# CY8C5888LTQ_LP097 register map
File version: 0.1
CY8C58LP
Registers are 8-bit, read-write, no defined reset value unless marked. A register's access mark holds for its fields unless they carry their own. Offsets are from the block's base; lines under a group give offsets from that group; [hi:lo] are bit positions; {n}, {i} and the like mark numbered series; 'fields as' and 'values as' point back to an identical list; <NAME> marks a mode.

## Memory map
0x00000000 ADC_SAR_1 — SAR ADC
0x00000000 I2C
0x00000000 EB_Status_Reg_2
0x00000000 EB_Status_Reg_1
0x00000000 USBUART — USBFS
0x00000000 ADC_SAR_2 — SAR ADC
0x00000000 ENGINE_DECODER
0x00000000 ENGINE_DECODER_Cnt16
0x00000000 ENGINE_Direction
0x00000000 UART_LOG — UART
0x00000000 ENGINE_PWM
0x00000000 UART_PSOC — UART

## ADC_SAR_1 — SAR ADC
Base 0x00000000
0x40004614 SAR_TR0 — SAR trim register
{0x40005900+i} SAR_CSR{i} (i=0..6) — SAR status and control register {i}
0x40005B20 SAR_SW0 — SAR Analog Routing Register 0
{0x40005B20+i} SAR_SW{i} (i=2..4) — SAR Analog Routing Register {i}
0x40005B26 SAR_SW6 — SAR Analog Routing Register 6
0x40005B27 SAR_CLK — SAR Clock Selection Register
0x40005BA0 SAR_WRK 16-bit — SAR working register

## EB_Status_Reg_2
Base 0x00000000
0x40006566 EB_Status_Reg_2_STATUS_REG
0x40006586 EB_Status_Reg_2_MASK_REG
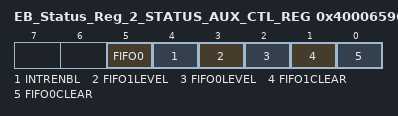
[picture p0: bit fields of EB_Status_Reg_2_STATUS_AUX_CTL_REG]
0x40006596 EB_Status_Reg_2_STATUS_AUX_CTL_REG
  [5] FIFO0 — FIFO0 clear
    1=ENABLED (Enable counter); 0=DISABLED (Disable counter)
  [4] INTRENBL — Enables or disables the Interrupt
    1=ENABLED (Interrupt enabled); 0=DISABLED (Interrupt disabled)
  [3] FIFO1LEVEL — FIFO level
    1=ENABLED (FIFO LVL: input mode: FIFO at least 1/2 empty; output mode: FIFO at least 1/2 full); 0=DISABLED (FIFO LVL: input mode: FIFO not full; output mode: FIFO not empty)
  [2] FIFO0LEVEL — FIFO level
    values as FIFO1LEVEL
  [1] FIFO1CLEAR — FIFO clear
    1=ENABLED (Clear FIFO state); 0=DISABLED (Normal FIFO operation)
  [0] FIFO0CLEAR — FIFO clear
    values as FIFO1CLEAR

## EB_Status_Reg_1
Base 0x00000000
0x40006568 EB_Status_Reg_1_STATUS_REG
0x40006588 EB_Status_Reg_1_MASK_REG
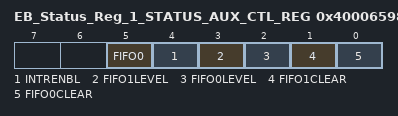
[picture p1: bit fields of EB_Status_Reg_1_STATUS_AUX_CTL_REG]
0x40006598 EB_Status_Reg_1_STATUS_AUX_CTL_REG
  [5] FIFO0 — FIFO0 clear
    1=ENABLED (Enable counter); 0=DISABLED (Disable counter)
  [4] INTRENBL — Enables or disables the Interrupt
    1=ENABLED (Interrupt enabled); 0=DISABLED (Interrupt disabled)
  [3] FIFO1LEVEL — FIFO level
    1=ENABLED (FIFO LVL: input mode: FIFO at least 1/2 empty; output mode: FIFO at least 1/2 full); 0=DISABLED (FIFO LVL: input mode: FIFO not full; output mode: FIFO not empty)
  [2] FIFO0LEVEL — FIFO level
    values as FIFO1LEVEL
  [1] FIFO1CLEAR — FIFO clear
    1=ENABLED (Clear FIFO state); 0=DISABLED (Normal FIFO operation)
  [0] FIFO0CLEAR — FIFO clear
    values as FIFO1CLEAR

## ADC_SAR_2 — SAR ADC
Base 0x00000000
0x40004616 SAR_TR0 — SAR trim register
{0x40005908+i} SAR_CSR{i} (i=0..6) — SAR status and control register {i}
0x40005B28 SAR_SW0 — SAR Analog Routing Register 0
{0x40005B28+i} SAR_SW{i} (i=2..4) — SAR Analog Routing Register {i}
0x40005B2E SAR_SW6 — SAR Analog Routing Register 6
0x40005B2F SAR_CLK — SAR Clock Selection Register
0x40005BA2 SAR_WRK 16-bit — SAR working register

## ENGINE_DECODER
Base 0x00000000
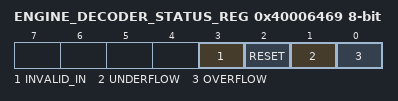
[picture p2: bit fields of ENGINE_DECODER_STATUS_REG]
0x40006469 ENGINE_DECODER_STATUS_REG — Quadrature Decoder Status Register
  [3] INVALID_IN ro — Invalid state transition on the A and B inputs
  [2] RESET ro — Counter Reset due index
  [1] UNDERFLOW ro — Counter underflow
  [0] OVERFLOW ro — Counter overflow
0x40006508 ENGINE_DECODER_Cnt16_COUNTER 16-bit — Counter value

## ENGINE_DECODER_Cnt16
Base 0x00000000; alternate view of ENGINE_DECODER
0x40006508 ENGINE_DECODER_Cnt16_COUNTER 16-bit — UDB.A0 - Current Counter Value
0x40006528 ENGINE_DECODER_Cnt16_PERIOD 16-bit — UDB.D0 - Assigned Period
0x40006538 ENGINE_DECODER_Cnt16_COMPARE 16-bit — UDB.D1 - Assigned Compare Value
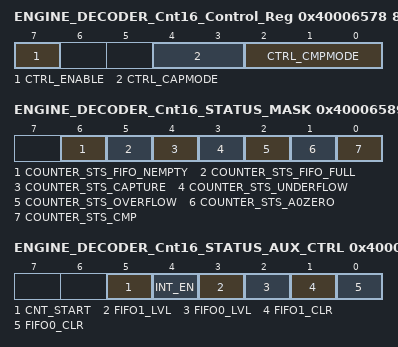
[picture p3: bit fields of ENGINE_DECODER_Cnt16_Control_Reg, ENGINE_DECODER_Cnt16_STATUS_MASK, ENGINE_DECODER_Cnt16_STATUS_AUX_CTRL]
0x40006578 ENGINE_DECODER_Cnt16_Control_Reg — UDB Control Register - Assigned Control Register Value
  [7] CTRL_ENABLE — Enable Counter
  [4:3] CTRL_CAPMODE — Capture mode
  [2:0] CTRL_CMPMODE — Compare mode
0x40006589 ENGINE_DECODER_Cnt16_STATUS_MASK — UDB Status bits Interrupt Mask Enable Register
  [6] COUNTER_STS_FIFO_NEMPTY — FIFO Not Empty Status
  [5] COUNTER_STS_FIFO_FULL — FIFO Full Status
  [4] COUNTER_STS_CAPTURE — Capture Status
  [3] COUNTER_STS_UNDERFLOW — Underflow status
  [2] COUNTER_STS_OVERFLOW — Overflow status
  [1] COUNTER_STS_A0ZERO — A0 Zero ouput status
  [0] COUNTER_STS_CMP — Compare output status
0x40006599 ENGINE_DECODER_Cnt16_STATUS_AUX_CTRL — UDB Auxilliary Control Register
  [5] CNT_START — FIFO0 clear
    0=E_CNT_START0 (Disable counter); 1=E_CNT_START1 (Enable counter)
  [4] INT_EN
    0=E_INT_EN0 (Interrupt disabled); 1=E_INT_EN1 (Interrupt enabled)
  [3] FIFO1_LVL — FIFO level
    0=E_FIFO_LVL_0 (FIFO LVL: input mode: FIFO not full; output mode: FIFO not empty); 1=E_FIFO_LVL_1 (FIFO LVL: input mode: FIFO at least 1/2 empty; output mode: FIFO at least 1/2 full)
  [2] FIFO0_LVL — FIFO level
    values as FIFO1_LVL
  [1] FIFO1_CLR — FIFO1 clear
    0=E_FIFO_CLR_0 (Normal FIFO operation); 1=E_FIFO_CLR_1 (Clear FIFO state)
  [0] FIFO0_CLR — FIFO0 clear
    values as FIFO1_CLR
